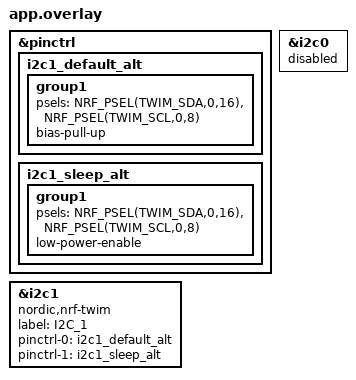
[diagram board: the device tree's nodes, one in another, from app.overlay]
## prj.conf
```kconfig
CONFIG_I2C=y
#need to turn these off for microbit v2 as they prevent low level fiddling with the i2c devices
CONFIG_GPIO=y
CONFIG_LIS2DH=n
CONFIG_LIS2MDL=n
```

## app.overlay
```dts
/*
 *
 * SPDX-License-Identifier: Apache-2.0
 */

&pinctrl {
    /* IMPORTANT!  There should not be a space before the : in the next line (and similar below) */


    i2c1_default_alt: i2c1_default_alt {
        group1 {
            psels = <NRF_PSEL(TWIM_SDA,0,16)>,
                    <NRF_PSEL(TWIM_SCL,0,8)>;
            bias-pull-up;
        };
    };
    i2c1_sleep_alt: i2c1_sleep_alt {
        group1 {
            psels = <NRF_PSEL(TWIM_SDA,0,16)>,
                    <NRF_PSEL(TWIM_SCL,0,8)>;
            low-power-enable;
        };
    };



};
&i2c0 {

    status = "disabled";
};

&i2c1 {
	compatible = "nordic,nrf-twim";
	status = "okay";
	label="I2C_1";
    pinctrl-0 = <&i2c1_default_alt>;
    pinctrl-1 = <&i2c1_sleep_alt>;
    pinctrl-names = "default", "sleep";
};
```

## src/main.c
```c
#include <zephyr/zephyr.h>
#include <zephyr/sys/printk.h>
#include <zephyr/device.h>
#include <zephyr/drivers/i2c.h>

/* https://tech.microbit.org/software/spec-i2c-protocol/#i2c-nrf--kl27-configcomms-interface */

#define READ_REQUEST_CMD_ID 0x10
#define READ_RESPONSE_CMD_ID 0x11
#define I2C_VER_PROPERTY_ID 0x02
#define DATA_SIZE_BYTES 0x02

#define KL27_CONFIG_INTERFACE_I2C_ADDR 0x70

static const struct device *i2c;

void main(void)
{
	int err;
	uint32_t num_bytes;
	uint8_t cmd[2] = {READ_REQUEST_CMD_ID, I2C_VER_PROPERTY_ID};
	uint8_t buf[5] = {READ_RESPONSE_CMD_ID, I2C_VER_PROPERTY_ID, DATA_SIZE_BYTES};

  	// Set up the I2C interface
	i2c = device_get_binding("I2C_1");
	if (i2c == NULL) {
		printf("Error acquiring i2c1 interface\n");
		return -1;
	}

	num_bytes = 2;
	err = i2c_write(i2c, cmd, num_bytes, KL27_CONFIG_INTERFACE_I2C_ADDR);
	if (err < 0) {
		printk("Error during I2C write\n");
		return -1;
	}

	do {
		num_bytes = 5;
		err = i2c_read(i2c, buf, num_bytes, KL27_CONFIG_INTERFACE_I2C_ADDR);
		if (err < 0) {
			printk("Error during I2C read\n");
			return -1;
		}
		k_msleep(100);
	} while (buf[2] == 0);

	printk("Cmd response: %02X\n", buf[0]);
	printk("Cmd response: %02X\n", buf[1]);
	printk("Cmd response: %02X\n", buf[2]);
	printk("Cmd response: %02X\n", buf[3]);
	printk("Cmd response: %02X\n", buf[4]);
}
```
